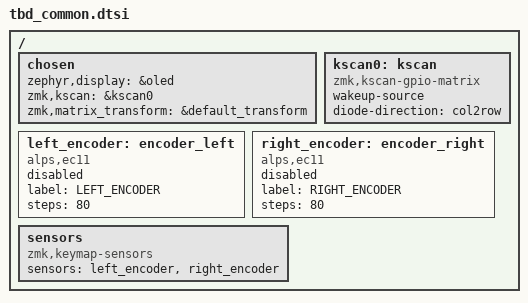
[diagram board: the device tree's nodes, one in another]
#include <dt-bindings/zmk/matrix_transform.h>

/ {
    chosen {
        zephyr,display = &oled;
		zmk,kscan = &kscan0;
		zmk,matrix_transform = &default_transform;
	}; 

    kscan0: kscan {
       compatible = "zmk,kscan-gpio-matrix";
       wakeup-source;
       diode-direction = "col2row";
    };


  left_encoder: encoder_left {
    compatible = "alps,ec11";
    label = "LEFT_ENCODER";
    steps = <80>;
    status = "disabled";  
  };

  right_encoder: encoder_right {
    compatible = "alps,ec11";
    label = "RIGHT_ENCODER";
    steps = <80>;
    status = "disabled";  
  };

   sensors {
     compatible = "zmk,keymap-sensors";
     sensors = <&left_encoder &right_encoder>;
    };
};

